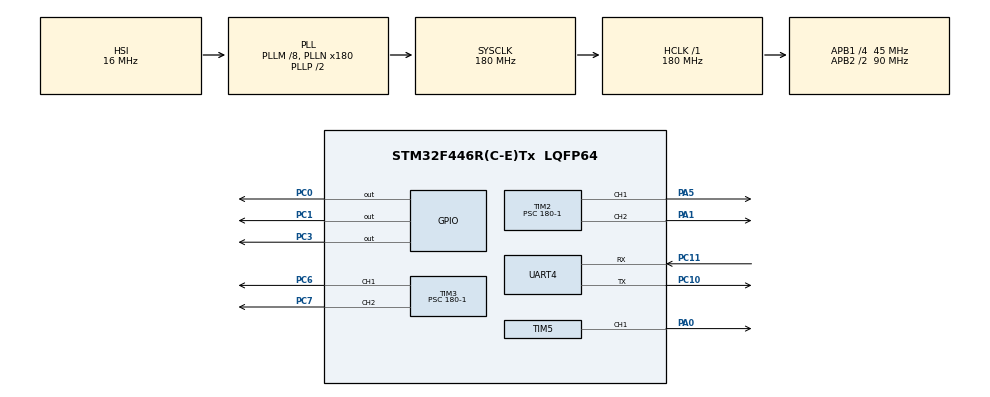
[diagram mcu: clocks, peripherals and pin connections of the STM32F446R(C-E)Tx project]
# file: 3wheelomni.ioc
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Mcu.Family=STM32F4
Mcu.Name=STM32F446R(C-E)Tx
Mcu.Package=LQFP64
NVIC.PriorityGroup=NVIC_PRIORITYGROUP_4
PA0-WKUP.Signal=S_TIM5_CH1
PA1.Signal=S_TIM2_CH2
PA5.Signal=S_TIM2_CH1_ETR
PC0.Signal=GPIO_Output
PC1.Signal=GPIO_Output
PC10.Mode=Asynchronous
PC10.Signal=UART4_TX
PC11.Mode=Asynchronous
PC11.Signal=UART4_RX
PC3.Signal=GPIO_Output
PC6.Signal=S_TIM3_CH1
PC7.Signal=S_TIM3_CH2
ProjectManager.HeapSize=0x200
ProjectManager.StackSize=0x400
ProjectManager.TargetToolchain=STM32CubeIDE
RCC.AHBFreq_Value=180000000
RCC.APB1CLKDivider=RCC_HCLK_DIV4
RCC.APB1Freq_Value=45000000
RCC.APB1TimFreq_Value=90000000
RCC.APB2CLKDivider=RCC_HCLK_DIV2
RCC.APB2Freq_Value=90000000
RCC.APB2TimFreq_Value=180000000
RCC.CortexFreq_Value=180000000
RCC.HCLKFreq_Value=180000000
RCC.PLLM=8
RCC.PLLN=180
RCC.SYSCLKFreq_VALUE=180000000
RCC.SYSCLKSource=RCC_SYSCLKSOURCE_PLLCLK
RCC.USBFreq_Value=180000000
RCC.VCOOutputFreq_Value=360000000
SH.S_TIM2_CH1_ETR.0=TIM2_CH1,PWM Generation1 CH1
SH.S_TIM2_CH2.0=TIM2_CH2,PWM Generation2 CH2
SH.S_TIM3_CH1.0=TIM3_CH1,PWM Generation1 CH1
SH.S_TIM3_CH2.0=TIM3_CH2,PWM Generation2 CH2
SH.S_TIM5_CH1.0=TIM5_CH1,PWM Generation1 CH1
TIM2.Channel-PWM\ Generation1\ CH1=TIM_CHANNEL_1
TIM2.Channel-PWM\ Generation2\ CH2=TIM_CHANNEL_2
TIM2.Period=1000-1
TIM2.Prescaler=180-1
TIM3.Channel-PWM\ Generation1\ CH1=TIM_CHANNEL_1
TIM3.Channel-PWM\ Generation2\ CH2=TIM_CHANNEL_2
TIM3.Period=1000-1
TIM3.Prescaler=180-1
TIM5.Channel-PWM\ Generation1\ CH1=TIM_CHANNEL_1
TIM5.Period=1000-1
TIM5.Prescaler=180-1
UART4.VirtualMode=Asynchronous
VP_TIM2_VS_ClockSourceINT.Mode=Internal
VP_TIM3_VS_ClockSourceINT.Mode=Internal
VP_TIM5_VS_ClockSourceINT.Mode=Internal
board=custom

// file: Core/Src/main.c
/* USER CODE BEGIN Header */
/**
  ******************************************************************************
  * @file           : main.c
  * @brief          : Main program body
  ******************************************************************************
  * @attention
  *
  * Copyright (c) 2024 STMicroelectronics.
  * All rights reserved.
  *
  * This software is licensed under terms that can be found in the LICENSE file
  * in the root directory of this software component.
  * If no LICENSE file comes with this software, it is provided AS-IS.
  *
  ******************************************************************************
  */
/* USER CODE END Header */
#include "main.h"

/* USER CODE BEGIN Includes */
#include<stdio.h>
#include<inttypes.h>

#include <stdbool.h>
/* USER CODE END Includes */

/* USER CODE BEGIN PD */
uint8_t rxbuff[16];

int slow=75;

int fast=400;

int Buff1=20;

int Buff2=-20;

int BuffP=50;

int BuffN=-50;

int32_t lx, ly, rx, ry, cro, squ, tri, cir, up, down, left, right, ll1, rr1, ll2, rr2;
/* USER CODE END PD */

TIM_HandleTypeDef htim2;
TIM_HandleTypeDef htim3;
TIM_HandleTypeDef htim5;

UART_HandleTypeDef huart4;

void SystemClock_Config(void);
static void MX_GPIO_Init(void);
static void MX_TIM2_Init(void);
static void MX_TIM5_Init(void);
static void MX_UART4_Init(void);
static void MX_TIM3_Init(void);

/* USER CODE BEGIN 0 */
long map(long x, long in_min, long in_max, long out_min, long out_max)
{
return (x - in_min) * (out_max - out_min) / (in_max - in_min) + out_min;
}
/* USER CODE END 0 */

int main(void)
{

  /* MCU Configuration--------------------------------------------------------*/

  /* Reset of all peripherals, Initializes the Flash interface and the Systick. */
  HAL_Init();

  /* Configure the system clock */
  SystemClock_Config();

  /* Initialize all configured peripherals */
  MX_GPIO_Init();
  MX_TIM2_Init();
  MX_TIM5_Init();
  MX_UART4_Init();
  MX_TIM3_Init();
  /* USER CODE BEGIN 2 */
  HAL_UART_Receive(&huart4, rxbuff, 64,1000);

  /* USER CODE END 2 */

  /* Infinite loop */
  while (1)
  {
	  HAL_StatusTypeDef status;

	 	 	   status=HAL_UART_Receive(&huart4, rxbuff,64,1000);

	 	 	   if (status == HAL_OK)

	 	 	   {

	 	 	   // Convert the received bytes to signed integers

	 	 	   lx = (rxbuff[1] & 0x80) ? (int32_t)rxbuff[1] - 256 : (int32_t)rxbuff[1];

	 	 	   ly = (rxbuff[2] & 0x80) ? (int32_t)rxbuff[2] - 256 : (int32_t)rxbuff[2];

	 	 	   rx = (rxbuff[3] & 0x80) ? (int32_t)rxbuff[3] - 256 : (int32_t)rxbuff[3];

	 	 	   ry = (rxbuff[4] & 0x80) ? (int32_t)rxbuff[4] - 256 : (int32_t)rxbuff[4];

	 	 	   cro= (rxbuff[5] & 0x80) ? (int32_t)rxbuff[5] - 256 : (int32_t)rxbuff[5];

	 	 	   squ= (rxbuff[6] & 0x80) ? (int32_t)rxbuff[6] - 256 : (int32_t)rxbuff[6];

	 	 	   tri= (rxbuff[7] & 0x80) ? (int32_t)rxbuff[7] - 256 : (int32_t)rxbuff[7];

	 	 	   cir= (rxbuff[8] & 0x80) ? (int32_t)rxbuff[8] - 256 : (int32_t)rxbuff[8];

	 	 	   up= (rxbuff[9] & 0x80) ? (int32_t)rxbuff[9] - 256 : (int32_t)rxbuff[9];

	 	 	   down= (rxbuff[10] & 0x80) ? (int32_t)rxbuff[10] - 256 : (int32_t)rxbuff[10];

	 	 	   left= (rxbuff[11] & 0x80) ? (int32_t)rxbuff[11] - 256 : (int32_t)rxbuff[11];

	 	 	   right=(rxbuff[12] & 0x80) ? (int32_t)rxbuff[12] - 256 : (int32_t)rxbuff[12];

	 	 	   ll1= (rxbuff[13] & 0x80) ? (int32_t)rxbuff[13] - 256 : (int32_t)rxbuff[13];

	 	 	   ll2= (rxbuff[14] & 0x80) ? (int32_t)rxbuff[14] - 256 : (int32_t)rxbuff[14];

	 	 	   rr1= (rxbuff[15] & 0x80) ? (int32_t)rxbuff[15] - 256 : (int32_t)rxbuff[15];

	 	 	   rr2= (rxbuff[16] & 0x80) ? (int32_t)rxbuff[16] - 256 : (int32_t)rxbuff[16];

	 	 	   // Print the received values

	 	 	   printf("Received Integers:\n");

	 	 	   printf("lx: %ld\n", lx);

	 	 	   printf("ly: %ld\n", ly);

	 	 	   printf("rx: %ld\n", rx);

	 	 	   printf("ry: %ld\n", ry);

	 	 	   printf("cro: %ld\n", cro);

	 	 	   printf("squ: %ld\n", squ);

	 	 	   printf("tri: %ld\n", tri);

	 	 	   printf("cir: %ld\n", cir);

	 	 	   printf("up: %ld\n", up);

	 	 	   printf("down: %ld\n", down);

	 	 	   printf("left: %ld\n", left);

	 	 	   printf("right: %ld\n", right);

	 	 	   printf("ll1: %ld\n", ll1);

	 	 	   printf("ll2: %ld\n", ll2);

	 	 	   printf("rr1: %ld\n", rr1);

	 	 	   printf("rr2: %ld\n", rr2);

	 	 	   }

	 	 	   else{

	 	 	   ry = 0;

	 	 	   rx = 0;

	 	 	   lx = 0;

	 	 	   ly = 0;

	 	 	   cro = 0;

	 	 	   squ = 0;

	 	 	   tri = 0;

	 	 	   cir = 0;

	 	 	   up = 0;

	 	 	   down = 0;

	 	 	   left = 0;

	 	 	   right = 0;

	 	 	   ll1=0;

	 	 	   ll2=0;

	 	 	   rr1=0;

	 	 	   rr2=0;

	 	 	   }

	 	 	   uint16_t dutycycle;

	 	 	  	dutycycle=0;

	 	 	  	//chassis

	 	 	  	//motors stop

	 	 	  	if(ly>=Buff2 && ly<=Buff1 && lx>=Buff2 && lx<=Buff1 && rx>=Buff2 && rx<=Buff1){
	 	 //
	 	 	  	 TIM3->CCR1 = 0;
	 	 	  	 TIM3->CCR2 = 0;
	 	 	  	 TIM5->CCR1 = 0;
	 	 //
	 	 	  	dutycycle=0;

	 	 //
	 	 	  	 HAL_TIM_PWM_Start(&htim3,TIM_CHANNEL_1);
	 	 	  	 HAL_TIM_PWM_Start(&htim3,TIM_CHANNEL_2);
	 	 	  	 HAL_TIM_PWM_Start(&htim5,TIM_CHANNEL_1);

	 	 	  	}
	 	 //
	 	 //	  	// else{
	 	 //
	 	 //	  	//forward
	 	 //
	 	 	  	else if( ly>=Buff1 && (lx<=BuffP && lx>=BuffN) )

	 	 	  	{

	 	 	  	dutycycle=map(ly,Buff1,127,0,fast);

	 	 	  	TIM3->CCR1 = dutycycle;
	 	 	  	TIM3->CCR2 = 0;
	 	 	  	TIM5->CCR1 = dutycycle;
	 	 //
	 	 //	  //
	 	 //
	 	 	  	HAL_TIM_PWM_Start(&htim3,TIM_CHANNEL_1);
	 	 	  	HAL_TIM_PWM_Start(&htim3,TIM_CHANNEL_2);
	 	 	  	HAL_TIM_PWM_Start(&htim5,TIM_CHANNEL_1);
	 	 //

	 	 	   HAL_GPIO_WritePin(GPIOC,GPIO_PIN_0,GPIO_PIN_SET);

	 //	 	   HAL_GPIO_WritePin(GPIOC,GPIO_PIN_1,GPIO_PIN_SET);

	 	 	   HAL_GPIO_WritePin(GPIOC,GPIO_PIN_3,GPIO_PIN_SET);

	 	 //	   	HAL_Delay(1000);

	 	 	   }

	 	 	   // backward

	 	 	   else if(ly<=Buff2 && (lx<=BuffP && lx>=BuffN) )

	 	 	   {

	 	 		 dutycycle=map(ly,-128,Buff2,fast,0);

	 	 	  	TIM3->CCR1 = dutycycle;
	 	 	  	TIM3->CCR2 = 0;
	 	 	  	TIM5->CCR1 = dutycycle;
	 	 //
	 	 //	  //
	 	 //
	 	 	  	HAL_TIM_PWM_Start(&htim3,TIM_CHANNEL_1);
	 	 	  	HAL_TIM_PWM_Start(&htim3,TIM_CHANNEL_2);
	 	 	  	HAL_TIM_PWM_Start(&htim5,TIM_CHANNEL_1);

	 	 	   HAL_GPIO_WritePin(GPIOC,GPIO_PIN_0,GPIO_PIN_RESET);

	 //	 	   HAL_GPIO_WritePin(GPIOC,GPIO_PIN_1,GPIO_PIN_RESET);

	 	 	   HAL_GPIO_WritePin(GPIOC,GPIO_PIN_3,GPIO_PIN_RESET);

	 	 //	    HAL_Delay(1000);

	 	 	   }

	 	 	   //	right

	 	 	   else if(lx>=Buff1 && (ly<=BuffP && ly>=BuffN))

	 	 	   {

	 	 	   dutycycle=map(lx,Buff1,127,0,fast);

	 	 	  	TIM3->CCR1 = dutycycle;
	 	 	  	TIM3->CCR2 = dutycycle;
	 	 	  	TIM5->CCR1 = 0;

	 	 	  	HAL_TIM_PWM_Start(&htim3,TIM_CHANNEL_1);
	 	 	  	HAL_TIM_PWM_Start(&htim3,TIM_CHANNEL_2);
	 	 	  	HAL_TIM_PWM_Start(&htim5,TIM_CHANNEL_1);

	 	 	  	HAL_GPIO_WritePin(GPIOC,GPIO_PIN_0,GPIO_PIN_SET);

	 	 	  	HAL_GPIO_WritePin(GPIOC,GPIO_PIN_1,GPIO_PIN_SET);

	 //	 	  	HAL_GPIO_WritePin(GPIOC,GPIO_PIN_3,GPIO_PIN_SET);

	 	 	   }

	 	 	   // left

	 	 	   else if(lx<=Buff2 && (ly<=BuffP && ly>=BuffN) )

	 	 	   {

	 	 	   dutycycle=map(lx,-128,Buff2,fast,0);

	 	 	  	TIM3->CCR1 = 0;
	 	 	  	TIM3->CCR2 = dutycycle;
	 	 	  	TIM5->CCR1 = dutycycle;

	 	 	  	HAL_TIM_PWM_Start(&htim3,TIM_CHANNEL_1);
	 	 	  	HAL_TIM_PWM_Start(&htim3,TIM_CHANNEL_2);
	 	 	  	HAL_TIM_PWM_Start(&htim5,TIM_CHANNEL_1);

	 //	 	  	HAL_GPIO_WritePin(GPIOC,GPIO_PIN_0,GPIO_PIN_SET);

	 	 	  	HAL_GPIO_WritePin(GPIOC,GPIO_PIN_1,GPIO_PIN_RESET);

	 	 	  	HAL_GPIO_WritePin(GPIOC,GPIO_PIN_3,GPIO_PIN_SET);

	 	 	   }

	 	 	   //clockwise

	 	 	   else if(rx>=Buff1 && (ry<=BuffP && ry>=BuffN) ){

	 	 	   dutycycle=map(rx,Buff1,127,0,100);

	 	 	  	TIM3->CCR1 = dutycycle;
	 	 	  	TIM3->CCR2 = dutycycle;
	 	 	  	TIM5->CCR1 = dutycycle;

	 	 	  	HAL_TIM_PWM_Start(&htim3,TIM_CHANNEL_1);
	 	 	  	HAL_TIM_PWM_Start(&htim3,TIM_CHANNEL_2);
	 	 	  	HAL_TIM_PWM_Start(&htim5,TIM_CHANNEL_1);

	 	 	  	HAL_GPIO_WritePin(GPIOC,GPIO_PIN_0,GPIO_PIN_SET);

	 	 	  	HAL_GPIO_WritePin(GPIOC,GPIO_PIN_1,GPIO_PIN_SET);

	 	 	  	HAL_GPIO_WritePin(GPIOC,GPIO_PIN_3,GPIO_PIN_SET);

	 	 	   }

	 	 	  // //anticlockwise

	 	 	   else if(rx<=Buff2 && (ry<=BuffP && ry>=BuffN) ){

	 	 	   dutycycle=map(rx,-128,Buff2,100,0);

	 	 	  	TIM3->CCR1 = dutycycle;
	 	 	  	TIM3->CCR2 = dutycycle;
	 	 	  	TIM5->CCR1 = dutycycle;

	 	 	  	HAL_TIM_PWM_Start(&htim3,TIM_CHANNEL_1);
	 	 	  	HAL_TIM_PWM_Start(&htim3,TIM_CHANNEL_2);
	 	 	  	HAL_TIM_PWM_Start(&htim5,TIM_CHANNEL_1);

	 	 	  	HAL_GPIO_WritePin(GPIOC,GPIO_PIN_0,GPIO_PIN_RESET);

	 	 	  	HAL_GPIO_WritePin(GPIOC,GPIO_PIN_1,GPIO_PIN_RESET);

	 	 	  	HAL_GPIO_WritePin(GPIOC,GPIO_PIN_3,GPIO_PIN_RESET);

	 	 	   }
  }
}

void SystemClock_Config(void)
{
  RCC_OscInitTypeDef RCC_OscInitStruct = {0};
  RCC_ClkInitTypeDef RCC_ClkInitStruct = {0};

  /** Configure the main internal regulator output voltage
  */
  __HAL_RCC_PWR_CLK_ENABLE();
  __HAL_PWR_VOLTAGESCALING_CONFIG(PWR_REGULATOR_VOLTAGE_SCALE1);

  /** Initializes the RCC Oscillators according to the specified parameters
  * in the RCC_OscInitTypeDef structure.
  */
  RCC_OscInitStruct.OscillatorType = RCC_OSCILLATORTYPE_HSI;
  RCC_OscInitStruct.HSIState = RCC_HSI_ON;
  RCC_OscInitStruct.HSICalibrationValue = RCC_HSICALIBRATION_DEFAULT;
  RCC_OscInitStruct.PLL.PLLState = RCC_PLL_ON;
  RCC_OscInitStruct.PLL.PLLSource = RCC_PLLSOURCE_HSI;
  RCC_OscInitStruct.PLL.PLLM = 8;
  RCC_OscInitStruct.PLL.PLLN = 180;
  RCC_OscInitStruct.PLL.PLLP = RCC_PLLP_DIV2;
  RCC_OscInitStruct.PLL.PLLQ = 2;
  RCC_OscInitStruct.PLL.PLLR = 2;
  if (HAL_RCC_OscConfig(&RCC_OscInitStruct) != HAL_OK)
  {
    Error_Handler();
  }

  /** Activate the Over-Drive mode
  */
  if (HAL_PWREx_EnableOverDrive() != HAL_OK)
  {
    Error_Handler();
  }

  /** Initializes the CPU, AHB and APB buses clocks
  */
  RCC_ClkInitStruct.ClockType = RCC_CLOCKTYPE_HCLK|RCC_CLOCKTYPE_SYSCLK
                              |RCC_CLOCKTYPE_PCLK1|RCC_CLOCKTYPE_PCLK2;
  RCC_ClkInitStruct.SYSCLKSource = RCC_SYSCLKSOURCE_PLLCLK;
  RCC_ClkInitStruct.AHBCLKDivider = RCC_SYSCLK_DIV1;
  RCC_ClkInitStruct.APB1CLKDivider = RCC_HCLK_DIV4;
  RCC_ClkInitStruct.APB2CLKDivider = RCC_HCLK_DIV2;

  if (HAL_RCC_ClockConfig(&RCC_ClkInitStruct, FLASH_LATENCY_5) != HAL_OK)
  {
    Error_Handler();
  }
}

static void MX_TIM2_Init(void)
{

  TIM_ClockConfigTypeDef sClockSourceConfig = {0};
  TIM_MasterConfigTypeDef sMasterConfig = {0};
  TIM_OC_InitTypeDef sConfigOC = {0};

  htim2.Instance = TIM2;
  htim2.Init.Prescaler = 180-1;
  htim2.Init.CounterMode = TIM_COUNTERMODE_UP;
  htim2.Init.Period = 1000-1;
  htim2.Init.ClockDivision = TIM_CLOCKDIVISION_DIV1;
  htim2.Init.AutoReloadPreload = TIM_AUTORELOAD_PRELOAD_DISABLE;
  if (HAL_TIM_Base_Init(&htim2) != HAL_OK)
  {
    Error_Handler();
  }
  sClockSourceConfig.ClockSource = TIM_CLOCKSOURCE_INTERNAL;
  if (HAL_TIM_ConfigClockSource(&htim2, &sClockSourceConfig) != HAL_OK)
  {
    Error_Handler();
  }
  if (HAL_TIM_PWM_Init(&htim2) != HAL_OK)
  {
    Error_Handler();
  }
  sMasterConfig.MasterOutputTrigger = TIM_TRGO_RESET;
  sMasterConfig.MasterSlaveMode = TIM_MASTERSLAVEMODE_DISABLE;
  if (HAL_TIMEx_MasterConfigSynchronization(&htim2, &sMasterConfig) != HAL_OK)
  {
    Error_Handler();
  }
  sConfigOC.OCMode = TIM_OCMODE_PWM1;
  sConfigOC.Pulse = 0;
  sConfigOC.OCPolarity = TIM_OCPOLARITY_HIGH;
  sConfigOC.OCFastMode = TIM_OCFAST_DISABLE;
  if (HAL_TIM_PWM_ConfigChannel(&htim2, &sConfigOC, TIM_CHANNEL_1) != HAL_OK)
  {
    Error_Handler();
  }
  if (HAL_TIM_PWM_ConfigChannel(&htim2, &sConfigOC, TIM_CHANNEL_2) != HAL_OK)
  {
    Error_Handler();
  }
  HAL_TIM_MspPostInit(&htim2);

}

static void MX_TIM3_Init(void)
{

  TIM_ClockConfigTypeDef sClockSourceConfig = {0};
  TIM_MasterConfigTypeDef sMasterConfig = {0};
  TIM_OC_InitTypeDef sConfigOC = {0};

  htim3.Instance = TIM3;
  htim3.Init.Prescaler = 180-1;
  htim3.Init.CounterMode = TIM_COUNTERMODE_UP;
  htim3.Init.Period = 1000-1;
  htim3.Init.ClockDivision = TIM_CLOCKDIVISION_DIV1;
  htim3.Init.AutoReloadPreload = TIM_AUTORELOAD_PRELOAD_DISABLE;
  if (HAL_TIM_Base_Init(&htim3) != HAL_OK)
  {
    Error_Handler();
  }
  sClockSourceConfig.ClockSource = TIM_CLOCKSOURCE_INTERNAL;
  if (HAL_TIM_ConfigClockSource(&htim3, &sClockSourceConfig) != HAL_OK)
  {
    Error_Handler();
  }
  if (HAL_TIM_PWM_Init(&htim3) != HAL_OK)
  {
    Error_Handler();
  }
  sMasterConfig.MasterOutputTrigger = TIM_TRGO_RESET;
  sMasterConfig.MasterSlaveMode = TIM_MASTERSLAVEMODE_DISABLE;
  if (HAL_TIMEx_MasterConfigSynchronization(&htim3, &sMasterConfig) != HAL_OK)
  {
    Error_Handler();
  }
  sConfigOC.OCMode = TIM_OCMODE_PWM1;
  sConfigOC.Pulse = 0;
  sConfigOC.OCPolarity = TIM_OCPOLARITY_HIGH;
  sConfigOC.OCFastMode = TIM_OCFAST_DISABLE;
  if (HAL_TIM_PWM_ConfigChannel(&htim3, &sConfigOC, TIM_CHANNEL_1) != HAL_OK)
  {
    Error_Handler();
  }
  if (HAL_TIM_PWM_ConfigChannel(&htim3, &sConfigOC, TIM_CHANNEL_2) != HAL_OK)
  {
    Error_Handler();
  }
  HAL_TIM_MspPostInit(&htim3);

}

static void MX_TIM5_Init(void)
{

  TIM_ClockConfigTypeDef sClockSourceConfig = {0};
  TIM_MasterConfigTypeDef sMasterConfig = {0};
  TIM_OC_InitTypeDef sConfigOC = {0};

  htim5.Instance = TIM5;
  htim5.Init.Prescaler = 180-1;
  htim5.Init.CounterMode = TIM_COUNTERMODE_UP;
  htim5.Init.Period = 1000-1;
  htim5.Init.ClockDivision = TIM_CLOCKDIVISION_DIV1;
  htim5.Init.AutoReloadPreload = TIM_AUTORELOAD_PRELOAD_DISABLE;
  if (HAL_TIM_Base_Init(&htim5) != HAL_OK)
  {
    Error_Handler();
  }
  sClockSourceConfig.ClockSource = TIM_CLOCKSOURCE_INTERNAL;
  if (HAL_TIM_ConfigClockSource(&htim5, &sClockSourceConfig) != HAL_OK)
  {
    Error_Handler();
  }
  if (HAL_TIM_PWM_Init(&htim5) != HAL_OK)
  {
    Error_Handler();
  }
  sMasterConfig.MasterOutputTrigger = TIM_TRGO_RESET;
  sMasterConfig.MasterSlaveMode = TIM_MASTERSLAVEMODE_DISABLE;
  if (HAL_TIMEx_MasterConfigSynchronization(&htim5, &sMasterConfig) != HAL_OK)
  {
    Error_Handler();
  }
  sConfigOC.OCMode = TIM_OCMODE_PWM1;
  sConfigOC.Pulse = 0;
  sConfigOC.OCPolarity = TIM_OCPOLARITY_HIGH;
  sConfigOC.OCFastMode = TIM_OCFAST_DISABLE;
  if (HAL_TIM_PWM_ConfigChannel(&htim5, &sConfigOC, TIM_CHANNEL_1) != HAL_OK)
  {
    Error_Handler();
  }
  HAL_TIM_MspPostInit(&htim5);

}

static void MX_UART4_Init(void)
{

  huart4.Instance = UART4;
  huart4.Init.BaudRate = 115200;
  huart4.Init.WordLength = UART_WORDLENGTH_8B;
  huart4.Init.StopBits = UART_STOPBITS_1;
  huart4.Init.Parity = UART_PARITY_NONE;
  huart4.Init.Mode = UART_MODE_TX_RX;
  huart4.Init.HwFlowCtl = UART_HWCONTROL_NONE;
  huart4.Init.OverSampling = UART_OVERSAMPLING_16;
  if (HAL_UART_Init(&huart4) != HAL_OK)
  {
    Error_Handler();
  }

}

static void MX_GPIO_Init(void)
{
  GPIO_InitTypeDef GPIO_InitStruct = {0};

  /* GPIO Ports Clock Enable */
  __HAL_RCC_GPIOC_CLK_ENABLE();
  __HAL_RCC_GPIOA_CLK_ENABLE();

  /*Configure GPIO pin Output Level */
  HAL_GPIO_WritePin(GPIOC, GPIO_PIN_0|GPIO_PIN_1|GPIO_PIN_3, GPIO_PIN_RESET);

  /*Configure GPIO pins : PC0 PC1 PC3 */
  GPIO_InitStruct.Pin = GPIO_PIN_0|GPIO_PIN_1|GPIO_PIN_3;
  GPIO_InitStruct.Mode = GPIO_MODE_OUTPUT_PP;
  GPIO_InitStruct.Pull = GPIO_NOPULL;
  GPIO_InitStruct.Speed = GPIO_SPEED_FREQ_LOW;
  HAL_GPIO_Init(GPIOC, &GPIO_InitStruct);

}

void Error_Handler(void)
{
  __disable_irq();
  while (1)
  {
  }
}
